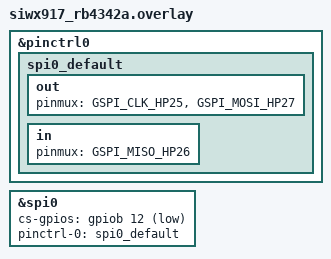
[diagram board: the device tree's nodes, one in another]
/*
 * Copyright (c) 2025 Silicon Laboratories Inc.
 *
 * SPDX-License-Identifier: Apache-2.0
 */

&pinctrl0 {
	spi0_default: spi0_default {
		out {
			pinmux = <GSPI_CLK_HP25>, <GSPI_MOSI_HP27>;
		};

		in {
			pinmux = <GSPI_MISO_HP26>;
		};
	};
};

#define SPI_LOOPBACK_FAST_HZ 10000000

spi_loopback: &spi0 {
	status = "okay";
	cs-gpios = <&gpiob 12 GPIO_ACTIVE_LOW>;
	pinctrl-0 = <&spi0_default>;
	pinctrl-names = "default";
};

#include "../spi-loopback.dtsi"
